# N32H488 register map
Vendor: Nationstech Ltd.; File version: 1.0
Registers are 32-bit, read-write, reset 0x0 unless marked. A register's access mark holds for its fields unless they carry their own. Offsets are from the block's base; [hi:lo] are bit positions; {n}, {i} and the like mark numbered series; 'fields as' and 'values as' point back to an identical list.

## I2S2_EXT — Inter—IC Sound
Base 0x40002600
Same registers: I2S3_EXT 0x40002A00
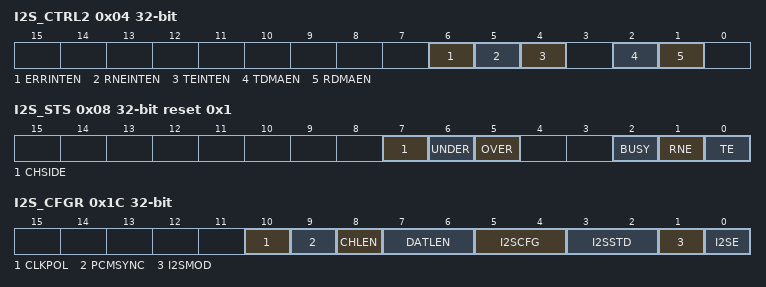
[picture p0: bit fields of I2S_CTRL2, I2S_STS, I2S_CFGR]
0x04 I2S_CTRL2
  [6] ERRINTEN, [5] RNEINTEN, [4] TEINTEN, [2] TDMAEN, [1] RDMAEN
0x08 I2S_STS reset 0x1
  [7] CHSIDE, [6] UNDER, [5] OVER, [2] BUSY, [1] RNE, [0] TE
0x0C I2S_DAT
  [15:0] DAT
0x1C I2S_CFGR
  [10] CLKPOL, [9] PCMSYNC, [8] CHLEN, [7:6] DATLEN, [5:4] I2SCFG, [3:2] I2SSTD, [1] I2SMOD, [0] I2SE

## DMA1 — Direct memory access controller
Base 0x40020000
Same registers: DMA2 0x40020400
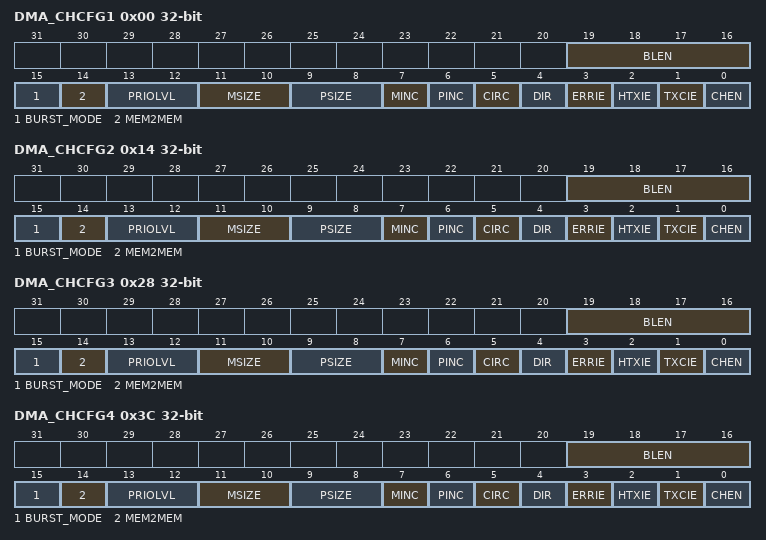
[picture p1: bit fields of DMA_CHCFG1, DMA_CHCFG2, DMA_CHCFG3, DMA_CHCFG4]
0x00 DMA_CHCFG1
  [19:16] BLEN, [15] BURST_MODE, [14] MEM2MEM, [13:12] PRIOLVL, [11:10] MSIZE, [9:8] PSIZE, [7] MINC, [6] PINC, [5] CIRC, [4] DIR, [3] ERRIE, [2] HTXIE, [1] TXCIE, [0] CHEN
0x04 DMA_MADDR1
  [31:0] ADDR
0x08 DMA_PADDR1
  [31:0] ADDR
0x0C DMA_CHSEL1
  [7:0] CH_SEL
0x10 DMA_TXNUM1
  [15:0] NDTX
0x14 DMA_CHCFG2
  fields as DMA_CHCFG1
0x18 DMA_MADDR2
  [31:0] ADDR
0x1C DMA_PADDR2
  [31:0] ADDR
0x20 DMA_CHSEL2
  [7:0] CH_SEL
0x24 DMA_TXNUM2
  [15:0] NDTX
0x28 DMA_CHCFG3
  fields as DMA_CHCFG1
0x2C DMA_MADDR3
  [31:0] ADDR
0x30 DMA_PADDR3
  [31:0] ADDR
0x34 DMA_CHSEL3
  [7:0] CH_SEL
0x38 DMA_TXNUM3
  [15:0] NDTX
0x3C DMA_CHCFG4
  fields as DMA_CHCFG1
0x40 DMA_MADDR4
  [31:0] ADDR
0x44 DMA_PADDR4
  [31:0] ADDR
0x48 DMA_CHSEL4
  [7:0] CH_SEL
0x4C DMA_TXNUM4
  [15:0] NDTX
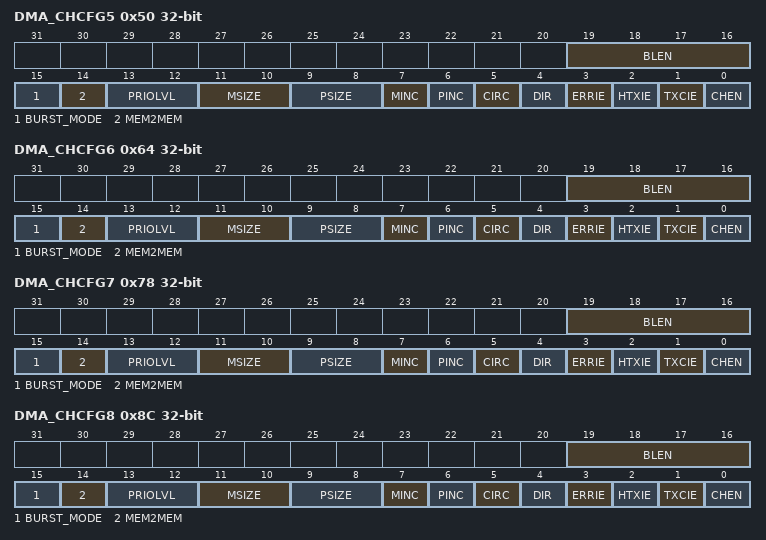
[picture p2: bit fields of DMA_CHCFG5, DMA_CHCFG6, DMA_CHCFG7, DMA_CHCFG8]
0x50 DMA_CHCFG5
  fields as DMA_CHCFG1
0x54 DMA_MADDR5
  [31:0] ADDR
0x58 DMA_PADDR5
  [31:0] ADDR
0x5C DMA_CHSEL5
  [7:0] CH_SEL
0x60 DMA_TXNUM5
  [15:0] NDTX
0x64 DMA_CHCFG6
  fields as DMA_CHCFG1
0x68 DMA_MADDR6
  [31:0] ADDR
0x6C DMA_PADDR6
  [31:0] ADDR
0x70 DMA_CHSEL6
  [7:0] CH_SEL
0x74 DMA_TXNUM6
  [15:0] NDTX
0x78 DMA_CHCFG7
  fields as DMA_CHCFG1
0x7C DMA_MADDR7
  [31:0] ADDR
0x80 DMA_PADDR7
  [31:0] ADDR
0x84 DMA_CHSEL7
  [7:0] CH_SEL
0x88 DMA_TXNUM7
  [15:0] NDTX
0x8C DMA_CHCFG8
  fields as DMA_CHCFG1
0x90 DMA_MADDR8
  [31:0] ADDR
0x94 DMA_PADDR8
  [31:0] ADDR
0x98 DMA_CHSEL8
  [7:0] CH_SEL
0x9C DMA_TXNUM8
  [15:0] NDTX
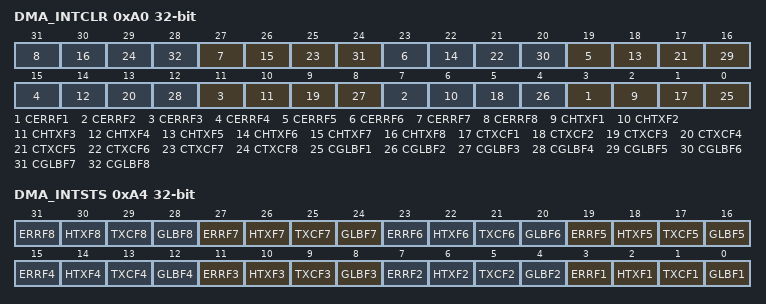
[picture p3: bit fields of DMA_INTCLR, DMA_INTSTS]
0xA0 DMA_INTCLR
  [4n-1] CERRF{n} (n=1..8), [4n-2] CHTXF{n} (n=1..8), [4n-3] CTXCF{n} (n=1..8), [4n-4] CGLBF{n} (n=1..8)
0xA4 DMA_INTSTS ro
  [4n-1] ERRF{n} (n=1..8), [4n-2] HTXF{n} (n=1..8), [4n-3] TXCF{n} (n=1..8), [4n-4] GLBF{n} (n=1..8)
0xA8 DMA_BURSTEN reset 0x1
  [0] BURST_BYPASS

## DVP — Digital video port
Base 0x40008400
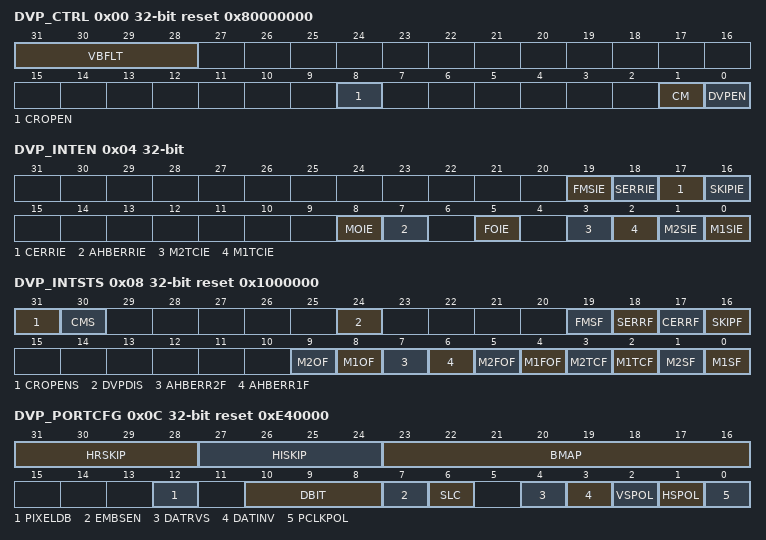
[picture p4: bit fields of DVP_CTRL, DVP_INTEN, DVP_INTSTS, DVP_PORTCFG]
0x00 DVP_CTRL reset 0x80000000
  [31:28] VBFLT, [8] CROPEN, [1] CM, [0] DVPEN
0x04 DVP_INTEN
  [19] FMSIE, [18] SERRIE, [17] CERRIE, [16] SKIPIE, [8] MOIE, [7] AHBERRIE, [5] FOIE, [3] M2TCIE, [2] M1TCIE, [1] M2SIE, [0] M1SIE
0x08 DVP_INTSTS reset 0x1000000
  [31] CROPENS ro, [30] CMS ro, [24] DVPDIS, [19] FMSF, [18] SERRF, [17] CERRF, [16] SKIPF, [9] M2OF, [8] M1OF, [7] AHBERR2F, [6] AHBERR1F, [5] M2FOF, [4] M1FOF, [3] M2TCF, [2] M1TCF, [1] M2SF, [0] M1SF
0x0C DVP_PORTCFG reset 0xE40000
  [31:28] HRSKIP, [27:24] HISKIP, [23:16] BMAP, [12] PIXELDB, [10:8] DBIT, [7] EMBSEN, [6] SLC, [4] DATRVS, [3] DATINV, [2] VSPOL, [1] HSPOL, [0] PCLKPOL
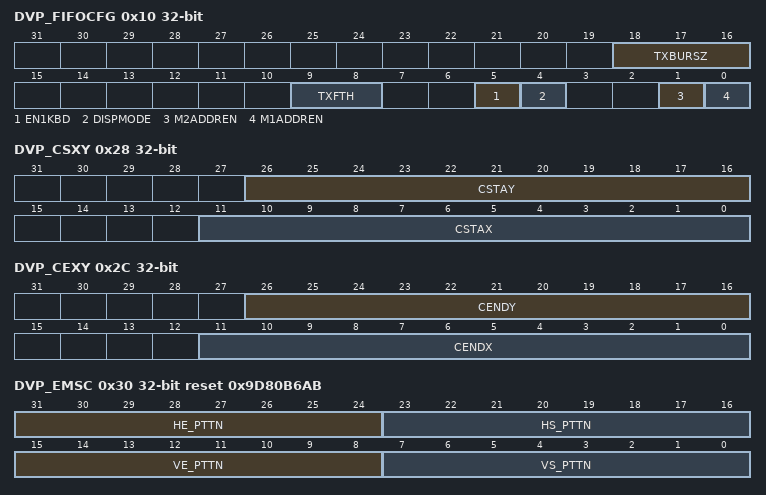
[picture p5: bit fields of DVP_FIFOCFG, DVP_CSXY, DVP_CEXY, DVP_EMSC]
0x10 DVP_FIFOCFG
  [18:16] TXBURSZ, [9:8] TXFTH, [5] EN1KBD, [4] DISPMODE, [1] M2ADDREN, [0] M1ADDREN
0x14 DVP_SMADDR1
  [31:0] MADDR
0x18 DVP_SMADDR2
  [31:0] MADDR
0x1C DVP_FBS
  [21:0] FMSIZE
0x20 DVP_FPBC1 ro
  [31:0] PIXLC
0x24 DVP_FPBC2 ro
  [31:0] PIXLC
0x28 DVP_CSXY
  [26:16] CSTAY, [11:0] CSTAX
0x2C DVP_CEXY
  [26:16] CENDY, [11:0] CENDX
0x30 DVP_EMSC reset 0x9D80B6AB
  [31:24] HE_PTTN, [23:16] HS_PTTN, [15:8] VE_PTTN, [7:0] VS_PTTN
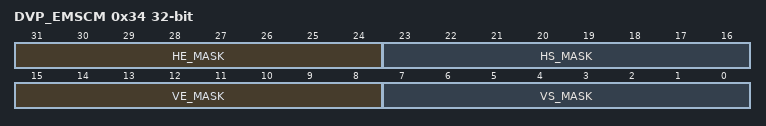
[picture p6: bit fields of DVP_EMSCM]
0x34 DVP_EMSCM
  [31:24] HE_MASK, [23:16] HS_MASK, [15:8] VE_MASK, [7:0] VS_MASK

## LPTIM1
Base 0x40006C00
Same registers: LPTIM2 0x40007000
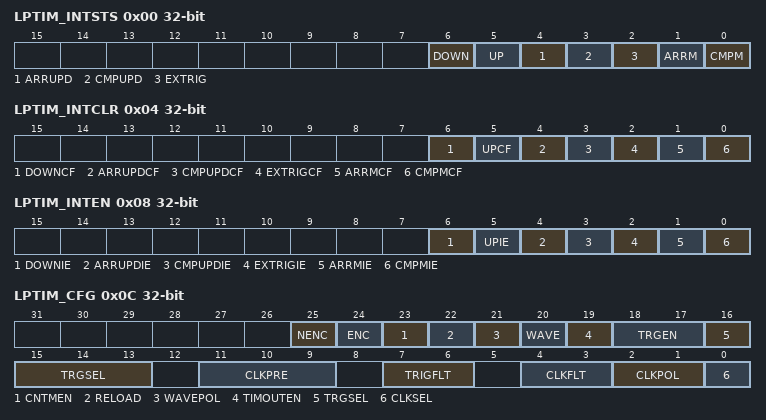
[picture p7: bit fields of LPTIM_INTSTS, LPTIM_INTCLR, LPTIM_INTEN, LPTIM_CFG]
0x00 LPTIM_INTSTS
  [6] DOWN, [5] UP, [4] ARRUPD, [3] CMPUPD, [2] EXTRIG, [1] ARRM, [0] CMPM
0x04 LPTIM_INTCLR
  [6] DOWNCF, [5] UPCF, [4] ARRUPDCF, [3] CMPUPDCF, [2] EXTRIGCF, [1] ARRMCF, [0] CMPMCF
0x08 LPTIM_INTEN
  [6] DOWNIE, [5] UPIE, [4] ARRUPDIE, [3] CMPUPDIE, [2] EXTRIGIE, [1] ARRMIE, [0] CMPMIE
0x0C LPTIM_CFG
  [25] NENC, [24] ENC, [23] CNTMEN, [22] RELOAD, [21] WAVEPOL, [20] WAVE, [19] TIMOUTEN, [18:17] TRGEN, [16:13] TRGSEL, [11:9] CLKPRE, [7:6] TRIGFLT, [4:3] CLKFLT, [2:1] CLKPOL, [0] CLKSEL
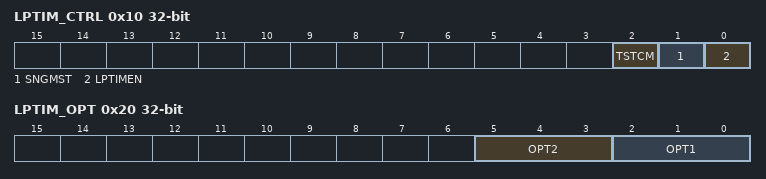
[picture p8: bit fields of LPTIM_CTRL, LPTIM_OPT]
0x10 LPTIM_CTRL
  [2] TSTCM, [1] SNGMST, [0] LPTIMEN
0x14 LPTIM_CMP
  [15:0] CMPVAL
0x18 LPTIM_ARR reset 0x1
  [15:0] ARRVAL
0x1C LPTIM_CNT
  [15:0] CNTVAL
0x20 LPTIM_OPT
  [5:3] OPT2, [2:0] OPT1
